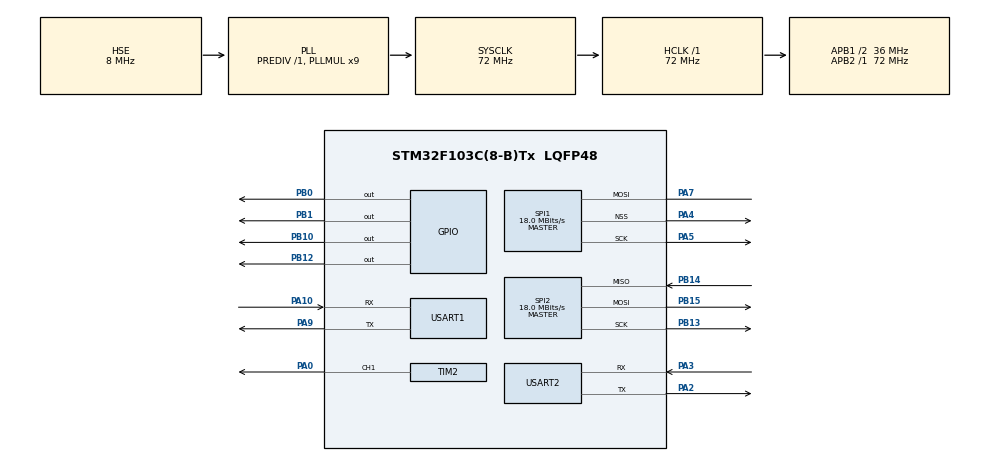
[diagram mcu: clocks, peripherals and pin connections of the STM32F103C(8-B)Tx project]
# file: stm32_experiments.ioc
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Dma.Request0=TIM2_UP
Dma.Request1=SPI1_TX
Dma.Request2=SPI2_TX
Dma.Request3=SPI2_RX
Dma.SPI1_TX.1.Direction=DMA_MEMORY_TO_PERIPH
Dma.SPI1_TX.1.Instance=DMA1_Channel3
Dma.SPI1_TX.1.MemDataAlignment=DMA_MDATAALIGN_BYTE
Dma.SPI1_TX.1.MemInc=DMA_MINC_ENABLE
Dma.SPI1_TX.1.Mode=DMA_NORMAL
Dma.SPI1_TX.1.PeriphDataAlignment=DMA_PDATAALIGN_BYTE
Dma.SPI1_TX.1.PeriphInc=DMA_PINC_DISABLE
Dma.SPI1_TX.1.Priority=DMA_PRIORITY_LOW
Dma.SPI2_RX.3.Direction=DMA_PERIPH_TO_MEMORY
Dma.SPI2_RX.3.Instance=DMA1_Channel4
Dma.SPI2_RX.3.MemDataAlignment=DMA_MDATAALIGN_BYTE
Dma.SPI2_RX.3.MemInc=DMA_MINC_ENABLE
Dma.SPI2_RX.3.Mode=DMA_NORMAL
Dma.SPI2_RX.3.PeriphDataAlignment=DMA_PDATAALIGN_BYTE
Dma.SPI2_RX.3.PeriphInc=DMA_PINC_DISABLE
Dma.SPI2_RX.3.Priority=DMA_PRIORITY_LOW
Dma.SPI2_TX.2.Direction=DMA_MEMORY_TO_PERIPH
Dma.SPI2_TX.2.Instance=DMA1_Channel5
Dma.SPI2_TX.2.MemDataAlignment=DMA_MDATAALIGN_BYTE
Dma.SPI2_TX.2.MemInc=DMA_MINC_DISABLE
Dma.SPI2_TX.2.Mode=DMA_NORMAL
Dma.SPI2_TX.2.PeriphDataAlignment=DMA_PDATAALIGN_BYTE
Dma.SPI2_TX.2.PeriphInc=DMA_PINC_DISABLE
Dma.SPI2_TX.2.Priority=DMA_PRIORITY_LOW
Dma.TIM2_UP.0.Direction=DMA_MEMORY_TO_PERIPH
Dma.TIM2_UP.0.Instance=DMA1_Channel2
Dma.TIM2_UP.0.MemDataAlignment=DMA_MDATAALIGN_WORD
Dma.TIM2_UP.0.MemInc=DMA_MINC_ENABLE
Dma.TIM2_UP.0.Mode=DMA_NORMAL
Dma.TIM2_UP.0.PeriphDataAlignment=DMA_PDATAALIGN_WORD
Dma.TIM2_UP.0.PeriphInc=DMA_PINC_DISABLE
Dma.TIM2_UP.0.Priority=DMA_PRIORITY_HIGH
Mcu.Family=STM32F1
Mcu.Name=STM32F103C(8-B)Tx
Mcu.Package=LQFP48
Mcu.UserConstants=TIM2_PERIOD,1
NVIC.DMA1_Channel2_IRQn=true\:0\:0\:false\:false\:true\:false\:true\:true
NVIC.DMA1_Channel3_IRQn=true\:0\:0\:false\:false\:true\:false\:true\:true
NVIC.DMA1_Channel4_IRQn=true\:0\:0\:false\:false\:true\:false\:true\:true
NVIC.DMA1_Channel5_IRQn=true\:0\:0\:false\:false\:true\:false\:true\:true
NVIC.PriorityGroup=NVIC_PRIORITYGROUP_4
PA0-WKUP.Signal=S_TIM2_CH1_ETR
PA10.Mode=Asynchronous
PA10.Signal=USART1_RX
PA13.Mode=JTAG_5_pins
PA13.Signal=SYS_JTMS-SWDIO
PA14.Mode=JTAG_5_pins
PA14.Signal=SYS_JTCK-SWCLK
PA15.Mode=JTAG_5_pins
PA15.Signal=SYS_JTDI
PA2.Mode=Asynchronous
PA2.Signal=USART2_TX
PA3.Mode=Asynchronous
PA3.Signal=USART2_RX
PA4.Mode=NSS_Signal_Hard_Output
PA4.Signal=SPI1_NSS
PA5.Mode=Simplex_Bidirectional_Master
PA5.Signal=SPI1_SCK
PA7.Mode=Simplex_Bidirectional_Master
PA7.Signal=SPI1_MOSI
PA9.Mode=Asynchronous
PA9.Signal=USART1_TX
PB0.GPIO_Speed=GPIO_SPEED_FREQ_HIGH
PB0.Signal=GPIO_Output
PB1.GPIO_Speed=GPIO_SPEED_FREQ_HIGH
PB1.Signal=GPIO_Output
PB10.Signal=GPIO_Output
PB12.Signal=GPIO_Output
PB13.Mode=Full_Duplex_Master
PB13.Signal=SPI2_SCK
PB14.Mode=Full_Duplex_Master
PB14.Signal=SPI2_MISO
PB15.Mode=Full_Duplex_Master
PB15.Signal=SPI2_MOSI
PB3.Mode=JTAG_5_pins
PB3.Signal=SYS_JTDO-TRACESWO
PB4.Mode=JTAG_5_pins
PB4.Signal=SYS_NJTRST
PC14-OSC32_IN.Mode=LSE-External-Oscillator
PC14-OSC32_IN.Signal=RCC_OSC32_IN
PC15-OSC32_OUT.Mode=LSE-External-Oscillator
PC15-OSC32_OUT.Signal=RCC_OSC32_OUT
PD0-OSC_IN.Mode=HSE-External-Oscillator
PD0-OSC_IN.Signal=RCC_OSC_IN
PD1-OSC_OUT.Mode=HSE-External-Oscillator
PD1-OSC_OUT.Signal=RCC_OSC_OUT
ProjectManager.HeapSize=0x200
ProjectManager.StackSize=0x400
ProjectManager.TargetToolchain=STM32CubeIDE
RCC.ADCPresc=RCC_ADCPCLK2_DIV6
RCC.AHBFreq_Value=72000000
RCC.APB1CLKDivider=RCC_HCLK_DIV2
RCC.APB1Freq_Value=36000000
RCC.APB1TimFreq_Value=72000000
RCC.APB2Freq_Value=72000000
RCC.APB2TimFreq_Value=72000000
RCC.HCLKFreq_Value=72000000
RCC.PLLMUL=RCC_PLL_MUL9
RCC.PLLSourceVirtual=RCC_PLLSOURCE_HSE
RCC.RTCClockSelection=RCC_RTCCLKSOURCE_LSE
RCC.SYSCLKFreq_VALUE=72000000
RCC.SYSCLKSource=RCC_SYSCLKSOURCE_PLLCLK
RCC.USBFreq_Value=72000000
RTC.AutoPrediv=RTC_AUTO_1_SECOND
RTC.Format=RTC_FORMAT_BIN
SH.S_TIM2_CH1_ETR.0=TIM2_CH1,Output Compare1 CH1
SPI1.BaudRatePrescaler=SPI_BAUDRATEPRESCALER_4
SPI1.CalculateBaudRate=18.0 MBits/s
SPI1.Direction=SPI_DIRECTION_1LINE
SPI1.Mode=SPI_MODE_MASTER
SPI1.VirtualNSS=VM_NSSHARD
SPI1.VirtualType=VM_MASTER
SPI2.BaudRatePrescaler=SPI_BAUDRATEPRESCALER_2
SPI2.CalculateBaudRate=18.0 MBits/s
SPI2.DataSize=SPI_DATASIZE_8BIT
SPI2.Direction=SPI_DIRECTION_2LINES
SPI2.Mode=SPI_MODE_MASTER
SPI2.VirtualType=VM_MASTER
TIM2.AutoReloadPreload=TIM_AUTORELOAD_PRELOAD_ENABLE
TIM2.Channel-Output\ Compare1\ CH1=TIM_CHANNEL_1
TIM2.OCMode_1=TIM_OCMODE_TOGGLE
TIM2.Period=TIM2_PERIOD
TIM2.TIM_MasterOutputTrigger=TIM_TRGO_UPDATE
USART1.VirtualMode=VM_ASYNC
USART2.VirtualMode=VM_ASYNC
VP_RTC_VS_RTC_Activate.Mode=RTC_Enabled
VP_RTC_VS_RTC_Calendar.Mode=RTC_Calendar
VP_TIM2_VS_ClockSourceINT.Mode=Internal
board=custom

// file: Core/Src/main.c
/* USER CODE BEGIN Header */
/**
  ******************************************************************************
  * @file           : main.c
  * @brief          : Main program body
  ******************************************************************************
  * @attention
  *
  * Copyright (c) 2024 STMicroelectronics.
  * All rights reserved.
  *
  * This software is licensed under terms that can be found in the LICENSE file
  * in the root directory of this software component.
  * If no LICENSE file comes with this software, it is provided AS-IS.
  *
  ******************************************************************************
  */
/* USER CODE END Header */
#include "main.h"

/* USER CODE BEGIN Includes */
#include "user_main.h"
/* USER CODE END Includes */

RTC_HandleTypeDef hrtc;

SPI_HandleTypeDef hspi1;
SPI_HandleTypeDef hspi2;
DMA_HandleTypeDef hdma_spi1_tx;
DMA_HandleTypeDef hdma_spi2_tx;
DMA_HandleTypeDef hdma_spi2_rx;

TIM_HandleTypeDef htim2;
DMA_HandleTypeDef hdma_tim2_up;

UART_HandleTypeDef huart1;
UART_HandleTypeDef huart2;

void SystemClock_Config(void);
static void MX_GPIO_Init(void);
static void MX_DMA_Init(void);
static void MX_USART1_UART_Init(void);
static void MX_RTC_Init(void);
static void MX_SPI1_Init(void);
static void MX_USART2_UART_Init(void);
static void MX_TIM2_Init(void);
static void MX_SPI2_Init(void);

int main(void)
{

  /* MCU Configuration--------------------------------------------------------*/

  /* Reset of all peripherals, Initializes the Flash interface and the Systick. */
  HAL_Init();

  /* Configure the system clock */
  SystemClock_Config();

  /* Initialize all configured peripherals */
  MX_GPIO_Init();
  MX_DMA_Init();
  MX_USART1_UART_Init();
  MX_RTC_Init();
  MX_SPI1_Init();
  MX_USART2_UART_Init();
  MX_TIM2_Init();
  MX_SPI2_Init();
  /* USER CODE BEGIN 2 */
  user_main();
  /* USER CODE END 2 */

  /* Infinite loop */
  while (1)
  {

  }
}

void SystemClock_Config(void)
{
  RCC_OscInitTypeDef RCC_OscInitStruct = {0};
  RCC_ClkInitTypeDef RCC_ClkInitStruct = {0};
  RCC_PeriphCLKInitTypeDef PeriphClkInit = {0};

  /** Initializes the RCC Oscillators according to the specified parameters
  * in the RCC_OscInitTypeDef structure.
  */
  RCC_OscInitStruct.OscillatorType = RCC_OSCILLATORTYPE_HSE|RCC_OSCILLATORTYPE_LSE;
  RCC_OscInitStruct.HSEState = RCC_HSE_ON;
  RCC_OscInitStruct.HSEPredivValue = RCC_HSE_PREDIV_DIV1;
  RCC_OscInitStruct.LSEState = RCC_LSE_ON;
  RCC_OscInitStruct.HSIState = RCC_HSI_ON;
  RCC_OscInitStruct.PLL.PLLState = RCC_PLL_ON;
  RCC_OscInitStruct.PLL.PLLSource = RCC_PLLSOURCE_HSE;
  RCC_OscInitStruct.PLL.PLLMUL = RCC_PLL_MUL9;
  if (HAL_RCC_OscConfig(&RCC_OscInitStruct) != HAL_OK)
  {
    Error_Handler();
  }

  /** Initializes the CPU, AHB and APB buses clocks
  */
  RCC_ClkInitStruct.ClockType = RCC_CLOCKTYPE_HCLK|RCC_CLOCKTYPE_SYSCLK
                              |RCC_CLOCKTYPE_PCLK1|RCC_CLOCKTYPE_PCLK2;
  RCC_ClkInitStruct.SYSCLKSource = RCC_SYSCLKSOURCE_PLLCLK;
  RCC_ClkInitStruct.AHBCLKDivider = RCC_SYSCLK_DIV1;
  RCC_ClkInitStruct.APB1CLKDivider = RCC_HCLK_DIV2;
  RCC_ClkInitStruct.APB2CLKDivider = RCC_HCLK_DIV1;

  if (HAL_RCC_ClockConfig(&RCC_ClkInitStruct, FLASH_LATENCY_2) != HAL_OK)
  {
    Error_Handler();
  }
  PeriphClkInit.PeriphClockSelection = RCC_PERIPHCLK_RTC;
  PeriphClkInit.RTCClockSelection = RCC_RTCCLKSOURCE_LSE;
  if (HAL_RCCEx_PeriphCLKConfig(&PeriphClkInit) != HAL_OK)
  {
    Error_Handler();
  }
}

static void MX_RTC_Init(void)
{

  RTC_TimeTypeDef sTime = {0};
  RTC_DateTypeDef DateToUpdate = {0};

  /** Initialize RTC Only
  */
  hrtc.Instance = RTC;
  hrtc.Init.AsynchPrediv = RTC_AUTO_1_SECOND;
  hrtc.Init.OutPut = RTC_OUTPUTSOURCE_ALARM;
  if (HAL_RTC_Init(&hrtc) != HAL_OK)
  {
    Error_Handler();
  }

  /* USER CODE BEGIN Check_RTC_BKUP */
  // Check if Data stored in BackUp register1: No Need to write it and then turn LED1
  // Read the Back Up Register 1 Data
    if (HAL_RTCEx_BKUPRead(&hrtc, RTC_BKP_DR1) != 0xBEBE)
    {
       // Write Back Up Register 1 Data
       HAL_PWR_EnableBkUpAccess();
       // Writes a data in a RTC Backup data Register 1
       HAL_RTCEx_BKUPWrite(&hrtc, RTC_BKP_DR1, 0xBEBE);
       HAL_PWR_DisableBkUpAccess();
  /* USER CODE END Check_RTC_BKUP */

  /** Initialize RTC and set the Time and Date
  */
  sTime.Hours = 0;
  sTime.Minutes = 0;
  sTime.Seconds = 0;

  if (HAL_RTC_SetTime(&hrtc, &sTime, RTC_FORMAT_BIN) != HAL_OK)
  {
    Error_Handler();
  }
  DateToUpdate.WeekDay = RTC_WEEKDAY_MONDAY;
  DateToUpdate.Month = RTC_MONTH_JANUARY;
  DateToUpdate.Date = 1;
  DateToUpdate.Year = 0;

  if (HAL_RTC_SetDate(&hrtc, &DateToUpdate, RTC_FORMAT_BIN) != HAL_OK)
  {
    Error_Handler();
  }
  /* USER CODE BEGIN RTC_Init 2 */
    }
    else
    {

    }
  /* USER CODE END RTC_Init 2 */

}

static void MX_SPI1_Init(void)
{

  /* SPI1 parameter configuration*/
  hspi1.Instance = SPI1;
  hspi1.Init.Mode = SPI_MODE_MASTER;
  hspi1.Init.Direction = SPI_DIRECTION_1LINE;
  hspi1.Init.DataSize = SPI_DATASIZE_8BIT;
  hspi1.Init.CLKPolarity = SPI_POLARITY_LOW;
  hspi1.Init.CLKPhase = SPI_PHASE_1EDGE;
  hspi1.Init.NSS = SPI_NSS_HARD_OUTPUT;
  hspi1.Init.BaudRatePrescaler = SPI_BAUDRATEPRESCALER_4;
  hspi1.Init.FirstBit = SPI_FIRSTBIT_MSB;
  hspi1.Init.TIMode = SPI_TIMODE_DISABLE;
  hspi1.Init.CRCCalculation = SPI_CRCCALCULATION_DISABLE;
  hspi1.Init.CRCPolynomial = 10;
  if (HAL_SPI_Init(&hspi1) != HAL_OK)
  {
    Error_Handler();
  }

}

static void MX_SPI2_Init(void)
{

  /* SPI2 parameter configuration*/
  hspi2.Instance = SPI2;
  hspi2.Init.Mode = SPI_MODE_MASTER;
  hspi2.Init.Direction = SPI_DIRECTION_2LINES;
  hspi2.Init.DataSize = SPI_DATASIZE_8BIT;
  hspi2.Init.CLKPolarity = SPI_POLARITY_LOW;
  hspi2.Init.CLKPhase = SPI_PHASE_1EDGE;
  hspi2.Init.NSS = SPI_NSS_SOFT;
  hspi2.Init.BaudRatePrescaler = SPI_BAUDRATEPRESCALER_2;
  hspi2.Init.FirstBit = SPI_FIRSTBIT_MSB;
  hspi2.Init.TIMode = SPI_TIMODE_DISABLE;
  hspi2.Init.CRCCalculation = SPI_CRCCALCULATION_DISABLE;
  hspi2.Init.CRCPolynomial = 10;
  if (HAL_SPI_Init(&hspi2) != HAL_OK)
  {
    Error_Handler();
  }

}

static void MX_TIM2_Init(void)
{

  TIM_ClockConfigTypeDef sClockSourceConfig = {0};
  TIM_MasterConfigTypeDef sMasterConfig = {0};
  TIM_OC_InitTypeDef sConfigOC = {0};

  htim2.Instance = TIM2;
  htim2.Init.Prescaler = 0;
  htim2.Init.CounterMode = TIM_COUNTERMODE_UP;
  htim2.Init.Period = TIM2_PERIOD;
  htim2.Init.ClockDivision = TIM_CLOCKDIVISION_DIV1;
  htim2.Init.AutoReloadPreload = TIM_AUTORELOAD_PRELOAD_ENABLE;
  if (HAL_TIM_Base_Init(&htim2) != HAL_OK)
  {
    Error_Handler();
  }
  sClockSourceConfig.ClockSource = TIM_CLOCKSOURCE_INTERNAL;
  if (HAL_TIM_ConfigClockSource(&htim2, &sClockSourceConfig) != HAL_OK)
  {
    Error_Handler();
  }
  if (HAL_TIM_OC_Init(&htim2) != HAL_OK)
  {
    Error_Handler();
  }
  sMasterConfig.MasterOutputTrigger = TIM_TRGO_UPDATE;
  sMasterConfig.MasterSlaveMode = TIM_MASTERSLAVEMODE_DISABLE;
  if (HAL_TIMEx_MasterConfigSynchronization(&htim2, &sMasterConfig) != HAL_OK)
  {
    Error_Handler();
  }
  sConfigOC.OCMode = TIM_OCMODE_TOGGLE;
  sConfigOC.Pulse = 0;
  sConfigOC.OCPolarity = TIM_OCPOLARITY_HIGH;
  sConfigOC.OCFastMode = TIM_OCFAST_DISABLE;
  if (HAL_TIM_OC_ConfigChannel(&htim2, &sConfigOC, TIM_CHANNEL_1) != HAL_OK)
  {
    Error_Handler();
  }
  HAL_TIM_MspPostInit(&htim2);

}

static void MX_USART1_UART_Init(void)
{

  huart1.Instance = USART1;
  huart1.Init.BaudRate = 115200;
  huart1.Init.WordLength = UART_WORDLENGTH_8B;
  huart1.Init.StopBits = UART_STOPBITS_1;
  huart1.Init.Parity = UART_PARITY_NONE;
  huart1.Init.Mode = UART_MODE_TX_RX;
  huart1.Init.HwFlowCtl = UART_HWCONTROL_NONE;
  huart1.Init.OverSampling = UART_OVERSAMPLING_16;
  if (HAL_UART_Init(&huart1) != HAL_OK)
  {
    Error_Handler();
  }

}

static void MX_USART2_UART_Init(void)
{

  huart2.Instance = USART2;
  huart2.Init.BaudRate = 115200;
  huart2.Init.WordLength = UART_WORDLENGTH_8B;
  huart2.Init.StopBits = UART_STOPBITS_1;
  huart2.Init.Parity = UART_PARITY_NONE;
  huart2.Init.Mode = UART_MODE_TX_RX;
  huart2.Init.HwFlowCtl = UART_HWCONTROL_NONE;
  huart2.Init.OverSampling = UART_OVERSAMPLING_16;
  if (HAL_UART_Init(&huart2) != HAL_OK)
  {
    Error_Handler();
  }

}

static void MX_DMA_Init(void)
{

  /* DMA controller clock enable */
  __HAL_RCC_DMA1_CLK_ENABLE();

  /* DMA interrupt init */
  /* DMA1_Channel2_IRQn interrupt configuration */
  HAL_NVIC_SetPriority(DMA1_Channel2_IRQn, 0, 0);
  HAL_NVIC_EnableIRQ(DMA1_Channel2_IRQn);
  /* DMA1_Channel3_IRQn interrupt configuration */
  HAL_NVIC_SetPriority(DMA1_Channel3_IRQn, 0, 0);
  HAL_NVIC_EnableIRQ(DMA1_Channel3_IRQn);
  /* DMA1_Channel4_IRQn interrupt configuration */
  HAL_NVIC_SetPriority(DMA1_Channel4_IRQn, 0, 0);
  HAL_NVIC_EnableIRQ(DMA1_Channel4_IRQn);
  /* DMA1_Channel5_IRQn interrupt configuration */
  HAL_NVIC_SetPriority(DMA1_Channel5_IRQn, 0, 0);
  HAL_NVIC_EnableIRQ(DMA1_Channel5_IRQn);

}

static void MX_GPIO_Init(void)
{
  GPIO_InitTypeDef GPIO_InitStruct = {0};

  /* GPIO Ports Clock Enable */
  __HAL_RCC_GPIOC_CLK_ENABLE();
  __HAL_RCC_GPIOD_CLK_ENABLE();
  __HAL_RCC_GPIOA_CLK_ENABLE();
  __HAL_RCC_GPIOB_CLK_ENABLE();

  /*Configure GPIO pin Output Level */
  HAL_GPIO_WritePin(GPIOB, GPIO_PIN_0|GPIO_PIN_1|GPIO_PIN_10|GPIO_PIN_12, GPIO_PIN_RESET);

  /*Configure GPIO pins : PB0 PB1 */
  GPIO_InitStruct.Pin = GPIO_PIN_0|GPIO_PIN_1;
  GPIO_InitStruct.Mode = GPIO_MODE_OUTPUT_PP;
  GPIO_InitStruct.Pull = GPIO_NOPULL;
  GPIO_InitStruct.Speed = GPIO_SPEED_FREQ_HIGH;
  HAL_GPIO_Init(GPIOB, &GPIO_InitStruct);

  /*Configure GPIO pins : PB10 PB12 */
  GPIO_InitStruct.Pin = GPIO_PIN_10|GPIO_PIN_12;
  GPIO_InitStruct.Mode = GPIO_MODE_OUTPUT_PP;
  GPIO_InitStruct.Pull = GPIO_NOPULL;
  GPIO_InitStruct.Speed = GPIO_SPEED_FREQ_LOW;
  HAL_GPIO_Init(GPIOB, &GPIO_InitStruct);

}

void Error_Handler(void)
{
  __disable_irq();
  while (1)
  {
  }
}
